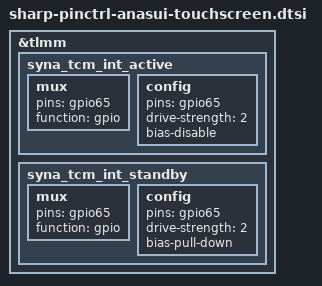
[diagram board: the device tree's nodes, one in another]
/* Copyright (c) 2016, The Linux Foundation. All rights reserved.
 *
 * This program is free software; you can redistribute it and/or modify
 * it under the terms of the GNU General Public License version 2 and
 * only version 2 as published by the Free Software Foundation.
 *
 * This program is distributed in the hope that it will be useful,
 * but WITHOUT ANY WARRANTY; without even the implied warranty of
 * MERCHANTABILITY or FITNESS FOR A PARTICULAR PURPOSE.  See the
 * GNU General Public License for more details.
 */

&tlmm {
	syna_tcm_int_active: syna_tcm_int_active {
		/* INT */
		mux {
			pins = "gpio65";
			function = "gpio";
		};

		config {
			pins = "gpio65";
			drive-strength = <2>;
			bias-disable;
		};
	};

	syna_tcm_int_standby: syna_tcm_int_standby {
		/* INT */
		mux {
			pins = "gpio65";
			function = "gpio";
		};

		config {
			pins = "gpio65";
			drive-strength = <2>;
			bias-pull-down;
		};
	};
};
